# STM32F405RGT6 register map
Vendor: STMicroelectronics; File version: 0.1.0
CPU: Cortex-M4 r0p1, little endian, MPU, FPU, DSP, VTOR, 4 interrupt priority bits
Registers are 32-bit, read-write, reset 0x0 unless marked. A register's access mark holds for its fields unless they carry their own. Offsets are from the block's base; [hi:lo] are bit positions.

## USART6 — Universal synchronous asynchronous receiver transmitter
Base 0x40011400
Same registers: USART2 0x40004400, USART3 0x40004800, USART1 0x40011000
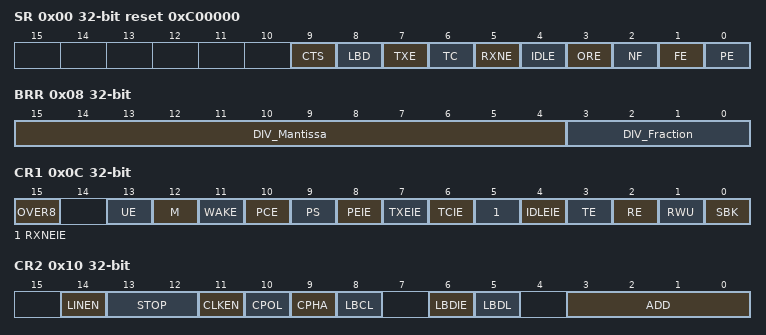
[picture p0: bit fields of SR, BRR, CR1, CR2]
0x00 SR access per field reset 0xC00000 — Status register
  [9] CTS rw — CTS flag
  [8] LBD rw — LIN break detection flag
  [7] TXE ro — Transmit data register empty
  [6] TC rw — Transmission complete
  [5] RXNE rw — Read data register not empty
  [4] IDLE ro — IDLE line detected
  [3] ORE ro — Overrun error
  [2] NF ro — Noise detected flag
  [1] FE ro — Framing error
  [0] PE ro — Parity error
0x04 DR — Data register
  [8:0] DR — Data value
0x08 BRR — Baud rate register
  [15:4] DIV_Mantissa — mantissa of USARTDIV
  [3:0] DIV_Fraction — fraction of USARTDIV
0x0C CR1 — Control register 1
  [15] OVER8 — Oversampling mode
  [13] UE — USART enable
  [12] M — Word length
  [11] WAKE — Wakeup method
  [10] PCE — Parity control enable
  [9] PS — Parity selection
  [8] PEIE — PE interrupt enable
  [7] TXEIE — TXE interrupt enable
  [6] TCIE — Transmission complete interrupt enable
  [5] RXNEIE — RXNE interrupt enable
  [4] IDLEIE — IDLE interrupt enable
  [3] TE — Transmitter enable
  [2] RE — Receiver enable
  [1] RWU — Receiver wakeup
  [0] SBK — Send break
0x10 CR2 — Control register 2
  [14] LINEN — LIN mode enable
  [13:12] STOP — STOP bits
  [11] CLKEN — Clock enable
  [10] CPOL — Clock polarity
  [9] CPHA — Clock phase
  [8] LBCL — Last bit clock pulse
  [6] LBDIE — LIN break detection interrupt enable
  [5] LBDL — lin break detection length
  [3:0] ADD — Address of the USART node
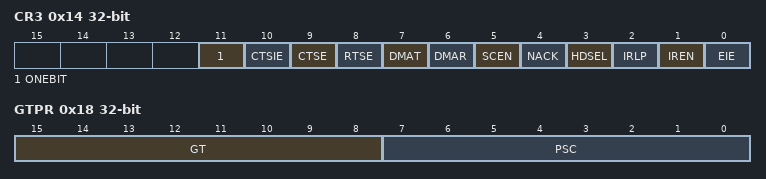
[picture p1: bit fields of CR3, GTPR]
0x14 CR3 — Control register 3
  [11] ONEBIT — One sample bit method enable
  [10] CTSIE — CTS interrupt enable
  [9] CTSE — CTS enable
  [8] RTSE — RTS enable
  [7] DMAT — DMA enable transmitter
  [6] DMAR — DMA enable receiver
  [5] SCEN — Smartcard mode enable
  [4] NACK — Smartcard NACK enable
  [3] HDSEL — Half-duplex selection
  [2] IRLP — IrDA low-power
  [1] IREN — IrDA mode enable
  [0] EIE — Error interrupt enable
0x18 GTPR — Guard time and prescaler register
  [15:8] GT — Guard time value
  [7:0] PSC — Prescaler value

## DAC1 — Digital-to-analog converter
Base 0x40007400
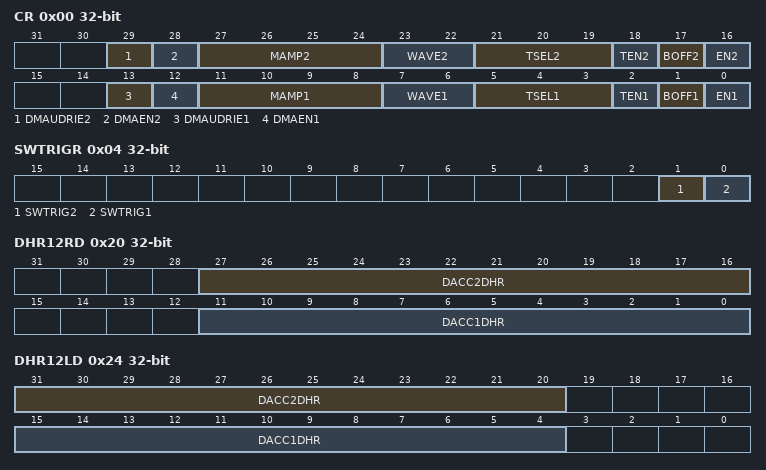
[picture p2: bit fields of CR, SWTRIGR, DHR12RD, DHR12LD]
0x00 CR — control register
  [29] DMAUDRIE2 — DAC channel2 DMA underrun interrupt enable
  [28] DMAEN2 — DAC channel2 DMA enable
  [27:24] MAMP2 — DAC channel2 mask/amplitude selector
  [23:22] WAVE2 — DAC channel2 noise/triangle wave generation enable
  [21:19] TSEL2 — DAC channel2 trigger selection
  [18] TEN2 — DAC channel2 trigger enable
  [17] BOFF2 — DAC channel2 output buffer disable
  [16] EN2 — DAC channel2 enable
  [13] DMAUDRIE1 — DAC channel1 DMA Underrun Interrupt enable
  [12] DMAEN1 — DAC channel1 DMA enable
  [11:8] MAMP1 — DAC channel1 mask/amplitude selector
  [7:6] WAVE1 — DAC channel1 noise/triangle wave generation enable
  [5:3] TSEL1 — DAC channel1 trigger selection
  [2] TEN1 — DAC channel1 trigger enable
  [1] BOFF1 — DAC channel1 output buffer disable
  [0] EN1 — DAC channel1 enable
0x04 SWTRIGR wo — software trigger register
  [1] SWTRIG2 — DAC channel2 software trigger
  [0] SWTRIG1 — DAC channel1 software trigger
0x08 DHR12R1 — channel1 12-bit right-aligned data holding register
  [11:0] DACC1DHR — DAC channel1 12-bit right-aligned data
0x0C DHR12L1 — channel1 12-bit left aligned data holding register
  [15:4] DACC1DHR — DAC channel1 12-bit left-aligned data
0x10 DHR8R1 — channel1 8-bit right aligned data holding register
  [7:0] DACC1DHR — DAC channel1 8-bit right-aligned data
0x14 DHR12R2 — channel2 12-bit right aligned data holding register
  [11:0] DACC2DHR — DAC channel2 12-bit right-aligned data
0x18 DHR12L2 — channel2 12-bit left aligned data holding register
  [15:4] DACC2DHR — DAC channel2 12-bit left-aligned data
0x1C DHR8R2 — channel2 8-bit right-aligned data holding register
  [7:0] DACC2DHR — DAC channel2 8-bit right-aligned data
0x20 DHR12RD — Dual DAC 12-bit right-aligned data holding register
  [27:16] DACC2DHR — DAC channel2 12-bit right-aligned data
  [11:0] DACC1DHR — DAC channel1 12-bit right-aligned data
0x24 DHR12LD — DUAL DAC 12-bit left aligned data holding register
  [31:20] DACC2DHR — DAC channel2 12-bit left-aligned data
  [15:4] DACC1DHR — DAC channel1 12-bit left-aligned data
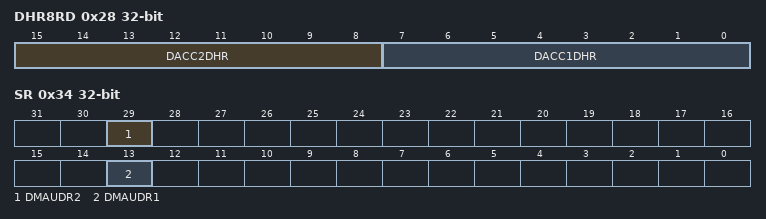
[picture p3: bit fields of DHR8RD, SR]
0x28 DHR8RD — DUAL DAC 8-bit right aligned data holding register
  [15:8] DACC2DHR — DAC channel2 8-bit right-aligned data
  [7:0] DACC1DHR — DAC channel1 8-bit right-aligned data
0x2C DOR1 ro — channel1 data output register
  [11:0] DACC1DOR — DAC channel1 data output
0x30 DOR2 ro — channel2 data output register
  [11:0] DACC2DOR — DAC channel2 data output
0x34 SR — status register
  [29] DMAUDR2 — DAC channel2 DMA underrun flag
  [13] DMAUDR1 — DAC channel1 DMA underrun flag
